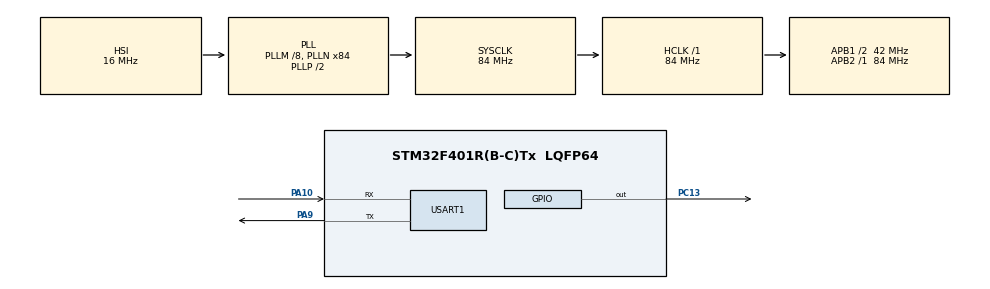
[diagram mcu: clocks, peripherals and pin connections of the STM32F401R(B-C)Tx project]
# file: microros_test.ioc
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Dma.Request0=USART1_RX
Dma.Request1=USART1_TX
Dma.USART1_RX.0.Direction=DMA_PERIPH_TO_MEMORY
Dma.USART1_RX.0.FIFOMode=DMA_FIFOMODE_DISABLE
Dma.USART1_RX.0.Instance=DMA2_Stream2
Dma.USART1_RX.0.MemDataAlignment=DMA_MDATAALIGN_BYTE
Dma.USART1_RX.0.MemInc=DMA_MINC_ENABLE
Dma.USART1_RX.0.Mode=DMA_CIRCULAR
Dma.USART1_RX.0.PeriphDataAlignment=DMA_PDATAALIGN_BYTE
Dma.USART1_RX.0.PeriphInc=DMA_PINC_DISABLE
Dma.USART1_RX.0.Priority=DMA_PRIORITY_VERY_HIGH
Dma.USART1_TX.1.Direction=DMA_MEMORY_TO_PERIPH
Dma.USART1_TX.1.FIFOMode=DMA_FIFOMODE_DISABLE
Dma.USART1_TX.1.Instance=DMA2_Stream7
Dma.USART1_TX.1.MemDataAlignment=DMA_MDATAALIGN_BYTE
Dma.USART1_TX.1.MemInc=DMA_MINC_ENABLE
Dma.USART1_TX.1.Mode=DMA_NORMAL
Dma.USART1_TX.1.PeriphDataAlignment=DMA_PDATAALIGN_BYTE
Dma.USART1_TX.1.PeriphInc=DMA_PINC_DISABLE
Dma.USART1_TX.1.Priority=DMA_PRIORITY_VERY_HIGH
FREERTOS.Tasks01=defaultTask,24,500,StartDefaultTask,Default,NULL,Static,defaultTaskBuffer,defaultTaskControlBlock
Mcu.Family=STM32F4
Mcu.Name=STM32F401R(B-C)Tx
Mcu.Package=LQFP64
NVIC.DMA2_Stream2_IRQn=true\:5\:0\:false\:false\:true\:true\:false\:true\:true
NVIC.DMA2_Stream7_IRQn=true\:5\:0\:false\:false\:true\:true\:false\:true\:true
NVIC.PriorityGroup=NVIC_PRIORITYGROUP_4
NVIC.TIM1_UP_TIM10_IRQn=true\:15\:0\:false\:false\:true\:false\:false\:true\:true
NVIC.TimeBase=TIM1_UP_TIM10_IRQn
NVIC.TimeBaseIP=TIM1
NVIC.USART1_IRQn=true\:5\:0\:false\:false\:true\:true\:false\:true\:true
PA10.Mode=Asynchronous
PA10.Signal=USART1_RX
PA9.Mode=Asynchronous
PA9.Signal=USART1_TX
PC13-ANTI_TAMP.Signal=GPIO_Output
PH0\ -\ OSC_IN.Mode=HSE-External-Oscillator
PH0\ -\ OSC_IN.Signal=RCC_OSC_IN
PH1\ -\ OSC_OUT.Mode=HSE-External-Oscillator
PH1\ -\ OSC_OUT.Signal=RCC_OSC_OUT
ProjectManager.HeapSize=0x200
ProjectManager.StackSize=0x400
ProjectManager.TargetToolchain=Makefile
RCC.48MHZClocksFreq_Value=42000000
RCC.AHBFreq_Value=84000000
RCC.APB1CLKDivider=RCC_HCLK_DIV2
RCC.APB1Freq_Value=42000000
RCC.APB1TimFreq_Value=84000000
RCC.APB2Freq_Value=84000000
RCC.APB2TimFreq_Value=84000000
RCC.CortexFreq_Value=84000000
RCC.HCLKFreq_Value=84000000
RCC.HSE_VALUE=25000000
RCC.HSI_VALUE=16000000
RCC.LSE_VALUE=32768
RCC.PLLM=8
RCC.PLLN=84
RCC.SYSCLKFreq_VALUE=84000000
RCC.SYSCLKSource=RCC_SYSCLKSOURCE_PLLCLK
RCC.VCOOutputFreq_Value=168000000
USART1.VirtualMode=VM_ASYNC
VP_FREERTOS_VS_CMSIS_V2.Mode=CMSIS_V2
VP_SYS_VS_tim1.Mode=TIM1
board=custom

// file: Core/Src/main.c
/* USER CODE BEGIN Header */
/**
  ******************************************************************************
  * @file           : main.c
  * @brief          : Main program body
  ******************************************************************************
  * @attention
  *
  * Copyright (c) 2025 STMicroelectronics.
  * All rights reserved.
  *
  * This software is licensed under terms that can be found in the LICENSE file
  * in the root directory of this software component.
  * If no LICENSE file comes with this software, it is provided AS-IS.
  *
  ******************************************************************************
  */
/* USER CODE END Header */
#include "main.h"
#include "cmsis_os.h"
#include "dma.h"
#include "usart.h"
#include "gpio.h"

void SystemClock_Config(void);
void MX_FREERTOS_Init(void);

int main(void)
{

  /* MCU Configuration--------------------------------------------------------*/

  /* Reset of all peripherals, Initializes the Flash interface and the Systick. */
  HAL_Init();

  /* Configure the system clock */
  SystemClock_Config();

  /* Initialize all configured peripherals */
  MX_GPIO_Init();
  MX_DMA_Init();
  MX_USART1_UART_Init();

  /* Init scheduler */
  osKernelInitialize();  /* Call init function for freertos objects (in cmsis_os2.c) */
  MX_FREERTOS_Init();

  /* Start scheduler */
  osKernelStart();

  /* We should never get here as control is now taken by the scheduler */

  /* Infinite loop */
  while (1)
  {

  }
}

void SystemClock_Config(void)
{
  RCC_OscInitTypeDef RCC_OscInitStruct = {0};
  RCC_ClkInitTypeDef RCC_ClkInitStruct = {0};

  /** Configure the main internal regulator output voltage
  */
  __HAL_RCC_PWR_CLK_ENABLE();
  __HAL_PWR_VOLTAGESCALING_CONFIG(PWR_REGULATOR_VOLTAGE_SCALE2);

  /** Initializes the RCC Oscillators according to the specified parameters
  * in the RCC_OscInitTypeDef structure.
  */
  RCC_OscInitStruct.OscillatorType = RCC_OSCILLATORTYPE_HSI;
  RCC_OscInitStruct.HSIState = RCC_HSI_ON;
  RCC_OscInitStruct.HSICalibrationValue = RCC_HSICALIBRATION_DEFAULT;
  RCC_OscInitStruct.PLL.PLLState = RCC_PLL_ON;
  RCC_OscInitStruct.PLL.PLLSource = RCC_PLLSOURCE_HSI;
  RCC_OscInitStruct.PLL.PLLM = 8;
  RCC_OscInitStruct.PLL.PLLN = 84;
  RCC_OscInitStruct.PLL.PLLP = RCC_PLLP_DIV2;
  RCC_OscInitStruct.PLL.PLLQ = 4;
  if (HAL_RCC_OscConfig(&RCC_OscInitStruct) != HAL_OK)
  {
    Error_Handler();
  }

  /** Initializes the CPU, AHB and APB buses clocks
  */
  RCC_ClkInitStruct.ClockType = RCC_CLOCKTYPE_HCLK|RCC_CLOCKTYPE_SYSCLK
                              |RCC_CLOCKTYPE_PCLK1|RCC_CLOCKTYPE_PCLK2;
  RCC_ClkInitStruct.SYSCLKSource = RCC_SYSCLKSOURCE_PLLCLK;
  RCC_ClkInitStruct.AHBCLKDivider = RCC_SYSCLK_DIV1;
  RCC_ClkInitStruct.APB1CLKDivider = RCC_HCLK_DIV2;
  RCC_ClkInitStruct.APB2CLKDivider = RCC_HCLK_DIV1;

  if (HAL_RCC_ClockConfig(&RCC_ClkInitStruct, FLASH_LATENCY_2) != HAL_OK)
  {
    Error_Handler();
  }
}

void HAL_TIM_PeriodElapsedCallback(TIM_HandleTypeDef *htim)
{
  if (htim->Instance == TIM1)
  {
    HAL_IncTick();
  }
}

void Error_Handler(void)
{
  __disable_irq();
  while (1)
  {
  }
}

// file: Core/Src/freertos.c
/* USER CODE BEGIN Header */
/**
  ******************************************************************************
  * File Name          : freertos.c
  * Description        : Code for freertos applications
  ******************************************************************************
  * @attention
  *
  * Copyright (c) 2025 STMicroelectronics.
  * All rights reserved.
  *
  * This software is licensed under terms that can be found in the LICENSE file
  * in the root directory of this software component.
  * If no LICENSE file comes with this software, it is provided AS-IS.
  *
  ******************************************************************************
  */
/* USER CODE END Header */

#include "FreeRTOS.h"
#include "task.h"
#include "main.h"
#include "cmsis_os.h"

/* USER CODE BEGIN Includes */
#include "usart.h"
#include <rcl/rcl.h>
#include <rcl/error_handling.h>
#include <rclc/rclc.h>
#include <rclc/executor.h>
#include <uxr/client/transport.h>
#include <rmw_microxrcedds_c/config.h>
#include <rmw_microros/rmw_microros.h>

#include <std_msgs/msg/int32.h>
/* USER CODE END Includes */

typedef StaticTask_t osStaticThreadDef_t;

/* Definitions for defaultTask */
osThreadId_t defaultTaskHandle;
uint32_t defaultTaskBuffer[ 500 ];
osStaticThreadDef_t defaultTaskControlBlock;
const osThreadAttr_t defaultTask_attributes = {
  .name = "defaultTask",
  .cb_mem = &defaultTaskControlBlock,
  .cb_size = sizeof(defaultTaskControlBlock),
  .stack_mem = &defaultTaskBuffer[0],
  .stack_size = sizeof(defaultTaskBuffer),
  .priority = (osPriority_t) osPriorityNormal,
};

/* USER CODE BEGIN FunctionPrototypes */
//Micro-ROS Builtin Functions
bool cubemx_transport_open(struct uxrCustomTransport * transport);
bool cubemx_transport_close(struct uxrCustomTransport * transport);
size_t cubemx_transport_write(struct uxrCustomTransport* transport, const uint8_t * buf, size_t len, uint8_t * err);
size_t cubemx_transport_read(struct uxrCustomTransport* transport, uint8_t* buf, size_t len, int timeout, uint8_t* err);

void * microros_allocate(size_t size, void * state);
void microros_deallocate(void * pointer, void * state);
void * microros_reallocate(void * pointer, size_t size, void * state);
void * microros_zero_allocate(size_t number_of_elements, size_t size_of_element, void * state);
// This function runs when a message is received on the topic
void led_subscription_callback(const void * msgin)
{
  // Cast the received message to the correct type
  const std_msgs__msg__Int32 * msg = (const std_msgs__msg__Int32 *)msgin;

  // Logic: 1 = LED ON, 0 = LED OFF
  if (msg->data == 1) {
    HAL_GPIO_WritePin(GPIOC, GPIO_PIN_13, GPIO_PIN_SET);
  } else {
    HAL_GPIO_WritePin(GPIOC, GPIO_PIN_13, GPIO_PIN_RESET);
  }
}
/* USER CODE END FunctionPrototypes */

void StartDefaultTask(void *argument);

void MX_FREERTOS_Init(void); /* (MISRA C 2004 rule 8.1) */

void MX_FREERTOS_Init(void) {

  /* Create the thread(s) */
  /* creation of defaultTask */
  defaultTaskHandle = osThreadNew(StartDefaultTask, NULL, &defaultTask_attributes);

}

void StartDefaultTask(void *argument)
{
  /* USER CODE BEGIN StartDefaultTask */

	 /* Infinite loop */
	    // micro-ROS configuration

	    rmw_uros_set_custom_transport(
	      true,
	      (void *) &huart1,
	      cubemx_transport_open,
	      cubemx_transport_close,
	      cubemx_transport_write,
	      cubemx_transport_read);

	    rcl_allocator_t freeRTOS_allocator = rcutils_get_zero_initialized_allocator();
	    freeRTOS_allocator.allocate = microros_allocate;
	    freeRTOS_allocator.deallocate = microros_deallocate;
	    freeRTOS_allocator.reallocate = microros_reallocate;
	    freeRTOS_allocator.zero_allocate =  microros_zero_allocate;

	    if (!rcutils_set_default_allocator(&freeRTOS_allocator)) {
	        printf("Error on default allocators (line %d)\n", __LINE__);
	    }

	    // micro-ROS app

	    rcl_subscription_t subscriber;
	    //rcl_publisher_t publisher;
	    std_msgs__msg__Int32 msg;
	    rclc_support_t support;
	    rcl_allocator_t allocator;
	    rcl_node_t node;
	    rclc_executor_t executor;
	    allocator = rcl_get_default_allocator();

	    //create init_options
	    rclc_support_init(&support, 0, NULL, &allocator);

	    // create node
	    //rclc_node_init_default(&node, "cubemx_node", "", &support);
	    rclc_node_init_default(&node, "stm32_led_node", "", &support);
	    /*Publisher Init Function
	     * Creates topic Named cubemx_publisher
	     *
	     * */

//	    rclc_publisher_init_default(
//	      &publisher,
//	      &node,
//	      ROSIDL_GET_MSG_TYPE_SUPPORT(std_msgs, msg, Int32),
//	      "cubemx_publisher");

	    /*Sunscriber function
	     * Topic Name : micro_ros_led
	     *
	     *
	     * */
	        rclc_subscription_init_default(
	            &subscriber,
	            &node,
	            ROSIDL_GET_MSG_TYPE_SUPPORT(std_msgs, msg, Int32),
	            "/micro_ros_led");
	    msg.data = 0;

	    /* ===== Initialize Executor =====*/
	    // The executor manages the incoming data and triggers the callback
	        // We have 1 handle (the subscriber)
	        rclc_executor_init(&executor, &support.context, 1, &allocator);

	        // Add the subscription to the executor
	        rclc_executor_add_subscription(&executor, &subscriber, &msg, &led_subscription_callback, ON_NEW_DATA);

	    for(;;)
	    {
	    	/*Publisher Code Example*/
//	      rcl_ret_t ret = rcl_publish(&publish&er, &msg, NULL);
//	      if (ret != RCL_RET_OK)
//	      {
//	        printf("Error publishing (line %d)\n", __LINE__);
//	      }
//
//	      msg.data++;
	    	/*Subscriber code example*/
	    	rclc_executor_spin_some(&executor, RCL_MS_TO_NS(10000000));

	    	      osDelay(10);
	    }
  /* USER CODE END StartDefaultTask */
}
